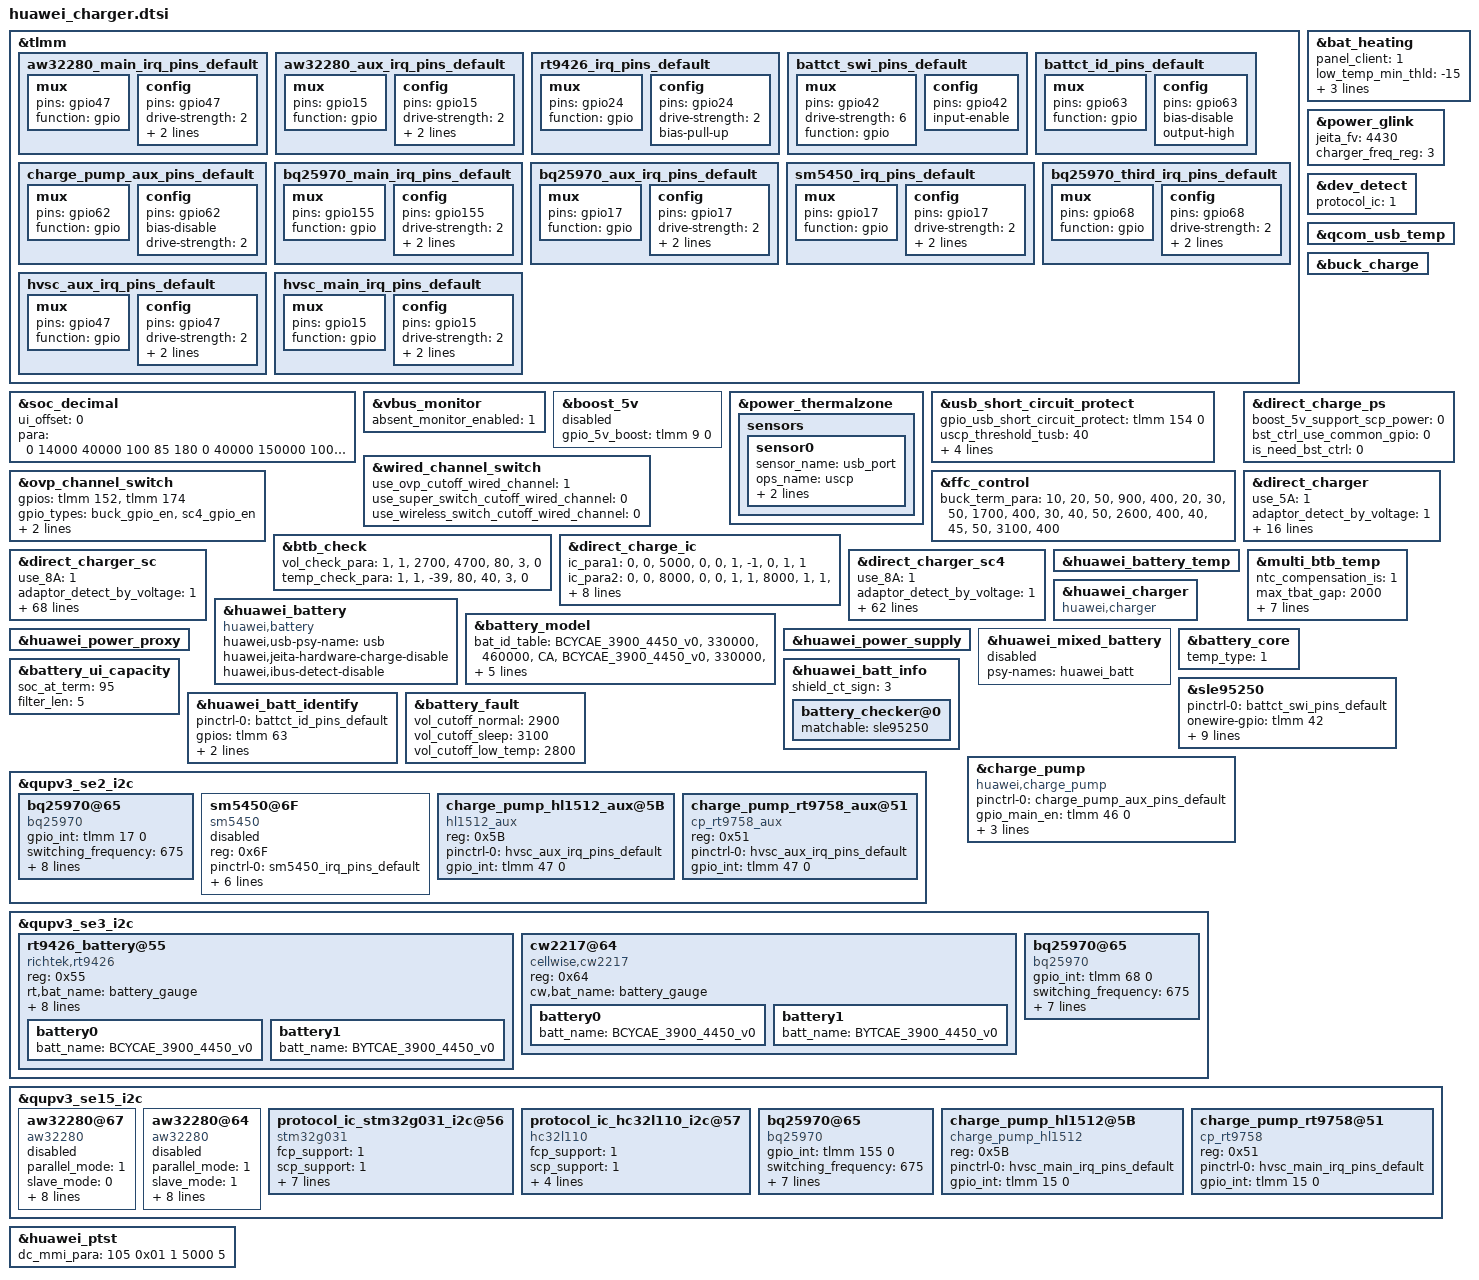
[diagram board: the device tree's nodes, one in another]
&tlmm {
	aw32280_main_irq_pins_default: aw32280_main_irq_pins_default {
		mux {
			pins = "gpio47";
			function = "gpio";
		};
		config {
			pins = "gpio47";
			drive-strength = <2>;
			bias-pull-up;
			input-enable;
		};
	};

	aw32280_aux_irq_pins_default: aw32280_aux_irq_pins_default {
		mux {
			pins = "gpio15";
			function = "gpio";
		};
		config {
			pins = "gpio15";
			drive-strength = <2>;
			bias-pull-up;
			input-enable;
		};
	};


	rt9426_irq_pins_default: rt9426_irq_pins_default {
		mux {
			pins = "gpio24";
			function = "gpio";
		};
		config {
			pins = "gpio24";
			drive-strength = <2>;
			bias-pull-up;
		};
	};
	battct_swi_pins_default: battct_swi_pins_default {
		mux {
			pins = "gpio42";
			drive-strength = <6>;
			function = "gpio";
		};
		config {
			pins = "gpio42";
			input-enable;
		};
	};
	battct_id_pins_default: battct_id_pins_default {
		mux {
			pins = "gpio63";
			function = "gpio";
		};
		config {
			pins = "gpio63";
			bias-disable;
			output-high;
		};
	};
	charge_pump_aux_pins_default: charge_pump_aux_pins_default {
		/* MCLK4 */
		mux {
			pins = "gpio62";
			function = "gpio";
		};
		config {
			pins = "gpio62";
			bias-disable; /* No PULL */
			drive-strength = <2>; /* 2 MA */
		};
	};
	bq25970_main_irq_pins_default: bq25970_main_irq_pins_default {
		mux {
			pins = "gpio155";
			function = "gpio";
		};
		config {
			pins = "gpio155";
			drive-strength = <2>;
			bias-pull-up;
			input-enable;
		};
	};

	bq25970_aux_irq_pins_default: bq25970_aux_irq_pins_default {
		mux {
			pins = "gpio17";
			function = "gpio";
		};
		config {
			pins = "gpio17";
			drive-strength = <2>;
			bias-pull-up;
			input-enable;
		};
	};

	sm5450_irq_pins_default: sm5450_irq_pins_default {
		mux {
			pins = "gpio17";
			function = "gpio";
		};
		config {
			pins = "gpio17";
			drive-strength = <2>;
			bias-pull-up;
			input-enable;
		};
	};

	bq25970_third_irq_pins_default: bq25970_third_irq_pins_default {
		mux {
			pins = "gpio68";
			function = "gpio";
		};
		config {
			pins = "gpio68";
			drive-strength = <2>;
			bias-pull-up;
			input-enable;
		};
	};

	hvsc_aux_irq_pins_default: hvsc_aux_irq_pins_default {
		mux {
			pins = "gpio47";
			function = "gpio";
		};
		config {
			pins = "gpio47";
			drive-strength = <2>;
			bias-pull-up;
			input-enable;
		};
	};

	hvsc_main_irq_pins_default: hvsc_main_irq_pins_default {
		mux {
			pins = "gpio15";
			function = "gpio";
		};
		config {
			pins = "gpio15";
			drive-strength = <2>;
			bias-pull-up;
			input-enable;
		};
	};
};

&bat_heating {
	panel_client = "1";
	low_temp_min_thld = "-15";
	low_temp_min_ibat = "-550";
	temp_para =
		"-32767", "0", "0",
		"0", "5", "-1",
		"5", "10", "400",
		"10", "20", "2500",
		"20", "45", "4500",
		"45", "32767", "0";
	status = "ok";
};

&soc_decimal {
	ui_offset = <0>;
	para = <
		0 14000 40000  100 85  180
		0 40000 150000 100 120 100
		1 20000 27000  100 85  140
		1 27000 100000 100 85  140
	>;
	status = "ok";
};

&power_glink {
	jeita_fv = <4430>;
	charger_freq_reg = <3>;
};

&dev_detect {
	protocol_ic = <1>;
};

&vbus_monitor {
	status = "ok";
	absent_monitor_enabled = <1>;
};

&boost_5v {
	gpio_5v_boost = <&tlmm 9 0>; /* GPIO_09 */
	status = "disabled";
};

&power_thermalzone {
	status = "ok";
	sensors{
		sensor0 {
			sensor_name = "usb_port";
			ops_name = "uscp";
			adc_channel = <0>;
			ntc_index = <5>;
		};
	};
};

&qcom_usb_temp {
	status = "ok";
};

&usb_short_circuit_protect {
	gpio_usb_short_circuit_protect = <&tlmm 154 0>; /* GPIO_154 */
	uscp_threshold_tusb = <40>;
	open_mosfet_temp = <30>;
	close_mosfet_temp = <10>;
	open_hiz_temp = <30>;
	interval_switch_temp = <15>;
	status = "ok";
};

&wired_channel_switch {
	use_ovp_cutoff_wired_channel = <1>;
	use_super_switch_cutoff_wired_channel = <0>;
	use_wireless_switch_cutoff_wired_channel = <0>;
	status = "ok";
};

&ovp_channel_switch {
	gpios = <&tlmm 152 0 &tlmm 174 0>;
	gpio_types = "buck_gpio_en", "sc4_gpio_en";
	gpio_en_status = <0 1>;
	gpio_low_by_set_input = <0>;
	status = "ok";
};

&buck_charge {
	status = "ok";
};

&ffc_control {
	status = "ok";
	buck_term_para =
		"10", "20", "50", "900", "400",
		"20", "30", "50", "1700", "400",
		"30", "40", "50", "2600", "400",
		"40", "45", "50", "3100", "400";
};

&btb_check {
	vol_check_para = "1", "1", "2700", "4700", "80", "3", "0";
	temp_check_para = "1", "1", "-39", "80", "40", "3", "0";
	status = "ok";
};

&direct_charge_ps {
	boost_5v_support_scp_power = <0>;
	bst_ctrl_use_common_gpio = <0>;
	is_need_bst_ctrl = <0>;
	status = "ok";
};

&direct_charge_ic {
	/* The IC_PARA table is used to find the relationship between chip and path */
	/* the chip's current passing capacity */
	/* and the sampling points of battery voltage and current */
	/* ic_index  path_index  max_ibat  ibat_sample_point  vbat_sample_point */
	ic_para1 =
		"0", "0", "5000", "0", "0",
		"1", "-1", "0", "1", "1";
	ic_para2 =
		"0", "0", "8000", "0", "0",
		"1", "1", "8000", "1", "1",
		"2", "1", "8000", "1", "1";
	ic_para3 =
		"0", "0", "9000", "0", "0",
		"1", "1", "8000", "1", "1",
		"2", "1", "8000", "1", "1";
	mode_para =
		"lvc_mode", "ic_para1",
		"sc_mode", "ic_para2",
		"sc4_mode", "ic_para3";
	use_two_stage = <1>;
	use_coul_ibat = <1>;
	use_coul_vbat = <1>;
	status = "ok";
};

&direct_charger {
	use_5A = <1>;
	adaptor_detect_by_voltage = <1>;
	need_wired_sw_off = <0>;
	volt_para =
		"4300", "4500", "4000",
		"4410", "4000", "2000";
	compensate_r = <11>;
	all_stage_compensate_r_en = <1>;
	cc_cable_detect_enable = <1>;
	vol_err_th = <250>;
	full_path_res_max = <300>;
	scp_work_on_charger = <1>;
	init_delt_vset = <300>;
	standard_cable_full_path_res_max = <300>;
	first_cc_stage_timer_in_min = <5>;
	stage_need_to_jump = "1";
	low_temp_hysteresis = <5>;
	temp_para =
		"-32767", "10", "0",
		"10", "45", "5000",
		"45", "32767", "0";
	rt_test_para =
		"1000", "105"; /* rt_curr_th rt_test_time */
	status = "ok";

};

&direct_charger_sc {
	use_8A = <1>;
	adaptor_detect_by_voltage = <1>;
	need_wired_sw_off = <0>;
	dc_volt_ratio = <2>;
	init_delt_vset = <450>;
	max_adaptor_vset = <11000>;
	init_adapter_vset = <8800>;
	vol_err_th = <500>;
	adaptor_leakage_current_th = <600>;
	vstep = <20>;
	min_dc_bat_vol = <3450>;
	max_dc_bat_vol = <4380>;
	max_current_for_none_standard_cable = <6000>;
	stop_charging_sleep_enable = <1>;
	delta_err = <200>;
	adaptor_antifake_check_enable = <1>;
	adaptor_antifake_key_index = <2>;
	support_multi_ic = <1>;
	multi_ic_ibat_th = <5000>;
	second_resist_check_en = <1>;
	ui_max_pwr = <40000>;
	product_max_pwr = <66000>;
	volt_para =
		"4150", "12000", "8000",
		"4250", "8000", "6000",
		"4300", "6000", "4000",
		"4430", "4000", "2800",
		"4460", "2800", "900";
	volt_para1 =
		"4200", "13200", "12000",
		"4300", "12000", "8000",
		"4400", "8000", "6000",
		"4430", "6000", "4800",
		"4460", "4800", "1600";
	volt_para2 =
		"4200", "13200", "12000",
		"4300", "12000", "8000",
		"4400", "8000", "6000",
		"4430", "6000", "4800",
		"4460", "4800", "2600";
	volt_para3 =
		"4200", "13200", "12000",
		"4300", "12000", "8000",
		"4400", "8000", "6000",
		"4430", "6000", "4800",
		"4460", "4800", "3100";
	time_para =
		"1380", "6200",
		"1320", "8300",
		"1020", "9300",
		"480", "9500",
		"0", "13200";
	bat_para =
		"CAE", "10", "20", "volt_para",
		"CAE", "20", "30", "volt_para1",
		"CAE", "30", "40", "volt_para2",
		"CAE", "40", "45", "volt_para3",
		"default", "10", "20", "volt_para",
		"default", "20", "30", "volt_para1",
		"default", "30", "40", "volt_para2",
		"default", "40", "45", "volt_para3";
	vstep_para =
			"2000", "80";
	compensate_r = <11>;
	all_stage_compensate_r_en = <1>;
	cc_cable_detect_enable = <1>;
	full_path_res_max = <500>;
	scp_work_on_charger = <1>;
	standard_cable_full_path_res_max = <500>;
	first_cc_stage_timer_in_min = <14>;
	stage_need_to_jump = "-1";
	low_temp_hysteresis = <5>;
	rt_test_para =
		/* first:sc second:mainsc third:auxsc */
		"500", "105",
		"500", "105",
		"500", "105";
	current_ratio =
		"3", "4", "12", "2", "-1",
		"3", "5", "10", "1", "8000",
		"0", "5", "10", "0", "0";
	vbat_error =
		"3", "140", "2", "-1",
		"3", "100", "1", "0";
	temp_para =
		"-32767", "10", "0",
		"10", "45", "13200",
		"45", "32767", "0";
	resist_para =
		"0", "300", "6000",
		"300", "600", "4000";
	std_resist_para =
		"0", "300", "0",
		"300", "600", "4000";
	second_resist_para =
		"0", "180", "0",
		"180", "600", "8000";
	ctc_second_resist_para =
		"0", "250", "0",
		"250", "600", "8000";
	adapter_max_power_time_para =
		"3", "600", "6000",
		"4", "1200", "3000",
		"5", "600", "6000",
		"6", "600", "6000",
		"7", "600", "6000",
		"8", "600", "6000",
		"9", "1200", "3000",
		"10", "1200", "3000",
		"11", "120", "8000",
		"12", "600", "6000",
		"13", "600", "6000",
		"14", "600", "6000",
		"15", "1200", "3000",
		"16", "120", "8000",
		"18", "120", "8000",
		"24", "120", "8000",
		"25", "120", "8000",
		"28", "120", "7500";
	status = "ok";
};

&direct_charger_sc4 {
	use_8A = <1>;
	adaptor_detect_by_voltage = <1>;
	need_wired_sw_off = <1>;
	dc_volt_ratio = <4>;
	init_delt_vset = <900>;
	charge_time = <60>;
	max_adaptor_vset = <20000>;
	init_adapter_vset = <15000>;
	vol_err_th = <500>;
	adaptor_leakage_current_th = <600>;
	vstep = <40>;
	min_dc_bat_vol = <3450>;
	max_dc_bat_vol = <4380>;
	max_current_for_none_standard_cable = <12000>;
	delta_err = <800>;
	adaptor_antifake_check_enable = <1>;
	adaptor_antifake_key_index = <2>;
	support_multi_ic = <1>;
	multi_ic_ibat_th = <5000>;
	second_resist_check_en = <1>;
	ui_max_pwr = <40000>;
	product_max_pwr = <100000>;
	volt_para =
		"4150", "12000", "8000",
		"4250", "8000", "6000",
		"4300", "6000", "4000",
		"4430", "4000", "2800",
		"4460", "2800", "900";
	volt_para1 =
		"4100", "20000", "16000",
		"4200", "16000", "12000",
		"4300", "12000", "8000",
		"4400", "8000", "6000",
		"4430", "6000", "4800",
		"4460", "4800", "1600";
	volt_para2 =
		"4100", "20000", "16000",
		"4200", "16000", "12000",
		"4300", "12000", "8000",
		"4400", "8000", "6000",
		"4430", "6000", "4800",
		"4460", "4800", "2600";
	volt_para3 =
		"4100", "20000", "16000",
		"4200", "16000", "12000",
		"4300", "12000", "8000",
		"4400", "8000", "6000",
		"4430", "6000", "4800",
		"4460", "4800", "3100";
	time_para =
		"1140", "6200",
		"960", "8200",
		"300", "9200",
		"90", "13200",
		"0", "20000";
	bat_para =
		"CAE", "10", "20", "volt_para",
		"CAE", "20", "30", "volt_para1",
		"CAE", "30", "40", "volt_para2",
		"CAE", "40", "45", "volt_para3",
		"default", "10", "20", "volt_para",
		"default", "20", "30", "volt_para1",
		"default", "30", "40", "volt_para2",
		"default", "40", "45", "volt_para3";
	vstep_para =
			"2000", "160";
	compensate_r = <11>;
	all_stage_compensate_r_en = <1>;
	cc_cable_detect_enable = <1>;
	full_path_res_max = <580>;
	scp_work_on_charger = <1>;
	standard_cable_full_path_res_max = <580>;
	ctc_cable_full_path_res_max = <400>;
	first_cc_stage_timer_in_min = <14>;
	stage_need_to_jump = "-1";
	low_temp_hysteresis = <5>;
	rt_test_para =
		/* first:sc4 second:mainsc4 third:auxsc4 */
		"5000", "105",
		"500", "0",
		"500", "0";
	current_ratio =
		"3", "4", "12", "2", "-1",
		"3", "5", "10", "1", "8000",
		"0", "5", "10", "0", "0";
	vbat_error =
		"3", "140", "2", "-1",
		"3", "100", "1", "0";
	temp_para =
		"-32767", "10", "0",
		"10", "45", "20000",
		"45", "32767", "0";
	resist_para =
		"0", "380", "12000",
		"380", "600", "8000";
	std_resist_para =
		"0", "380", "0",
		"380", "600", "8000";
	second_resist_para =
		"0", "260", "0",
		"260", "600", "16000";
	ctc_second_resist_para =
		"0", "330", "0",
		"330", "600", "16000";
	status = "ok";
};

&huawei_battery_temp {
	status = "ok";
};

&multi_btb_temp {
	status = "ok";
	ntc_compensation_is = <1>;
	max_tbat_gap = <2000>;
	comp_para =
		"17000", "17000",
		"15000", "15000",
		"13000", "13000",
		"11000", "11000",
		"9000", "8000",
		"7000", "5000",
		"6000", "4000",
		"5000", "3000",
		"3000", "2000",
		"2000", "1000";
	comp_para1 =
		"0", "0";
	sensor-names =
		"battery_gauge", "comp_para",
		"bk_battery", "comp_para1";
};

&huawei_battery {
	compatible = "huawei,battery";
	status = "ok";
	huawei,usb-psy-name = "usb";
	huawei,jeita-hardware-charge-disable;
	huawei,ibus-detect-disable;
};

&huawei_charger {
	compatible = "huawei,charger";
	status = "ok";
};


&battery_model {
	bat_id_table =
		"BCYCAE_3900_4450_v0", "330000", "460000", "CA",
		"BCYCAE_3900_4450_v0", "330000", "460000", "CZ",
		"BYTCAE_3900_4450_v0", "330000", "460000", "YA",
		"BYTCAE_3900_4450_v0", "330000", "460000", "YZ";
	design_fcc = <3900>;
	id_adc_channel = <0>; /* useless but necessary for Qcom, set 0 as default */
	status = "ok";
};

&huawei_power_proxy {
	status = "ok";
};

&huawei_power_supply {
	 status = "ok";
};

&huawei_mixed_battery {
	psy-names = "huawei_batt";
	status = "disabled";
};

&battery_core {
	temp_type = <1>;
	status = "ok";
};

&battery_ui_capacity {
	soc_at_term = <95>;
	filter_len = <5>;
	status = "ok";
};

&sle95250 {
        pinctrl-names = "default";
        pinctrl-0 = <&battct_swi_pins_default>;
        onewire-gpio = <&tlmm 42 0>;
        product_id0 = <1>;
        product_id2 = <3>;
        gpio_sn_mode_val = <0>;
        dip_check = <0>;
        gpio_swi = <42>;
        gpio_id_mode = <63>;
        gpio_swi_drv = <2>;
        tau = /bits/ 8 <0xa>;
        tau_fastboot = <7>;
        status = "ok";
};

&huawei_batt_info {
        status = "ok";
        shield_ct_sign = <3>;
        battery_checker@0 {
                matchable = <&sle95250>;
                status = "ok";
        };
};

&huawei_batt_identify {
	pinctrl-names = "default";
	pinctrl-0 = <&battct_id_pins_default>;
	gpios = <&tlmm 63 0>;
	id_voltage_gpiov = <0 1>;
	id_sn_gpiov = <0 0>;
	status = "ok";
};

&battery_fault {
	vol_cutoff_normal = <2900>;
	vol_cutoff_sleep = <3100>;
	vol_cutoff_low_temp = <2800>;
	status = "ok";
};

&charge_pump {
	compatible = "huawei,charge_pump";
	pinctrl-names = "default";
	pinctrl-0 = <&charge_pump_aux_pins_default>;
	gpio_main_en = <&tlmm 46 0>;
	gpio_main_cp_en_val = <0>;
	gpio_aux_en = <&tlmm 62 0>;
	gpio_aux_cp_en_val = <0>;
	status = "ok";
};

&qupv3_se2_i2c {
	status = "ok";
	bq25970@65 {
		compatible = "bq25970";
		gpio_int = <&tlmm 17 0>;
		switching_frequency = <675>;
		reg = <0x65>;
		pinctrl-names = "default";
		pinctrl-0 = <&bq25970_aux_irq_pins_default>;
		ic_role = <1>;
		freq_para =
			"sc_sc8551", "300";
		ibus_low_deglitch = <5>;
		lvc_batinfo_enable = <1>;
		sense_r_actual = <10>;
		resume_need_wait_i2c = <1>;
		status = "ok";
	};

	sm5450@6F{
		compatible = "sm5450";
		reg = <0x6F>;
		pinctrl-names = "default";
		pinctrl-0 = <&sm5450_irq_pins_default>;
		intr_gpio_num = <17>; /* direct defined GPIO num */
		intr_gpio = <&tlmm 17 0>;
		fcp_support = <1>;
		scp_support = <1>;
		sense_r_actual = <10>;
		ic_role = <1>;
		status = "disabled";
	};

	charge_pump_hl1512_aux@5B {
		compatible = "hl1512_aux";
		reg = <0x5B>;
		pinctrl-names = "hvsc_aux_irq_pins_default";
		pinctrl-0 = <&hvsc_aux_irq_pins_default>;
		gpio_int = <&tlmm 47 0>;
		status = "ok";
	};

	charge_pump_rt9758_aux@51 {
		compatible = "cp_rt9758_aux";
		reg = <0x51>;
		pinctrl-names = "hvsc_aux_irq_pins_default";
		pinctrl-0 = <&hvsc_aux_irq_pins_default>;
		gpio_int = <&tlmm 47 0>;
		status = "ok";
	};
};

&qupv3_se3_i2c {
	status = "ok";
	rt9426_battery@55{
		reg = <0x55>;
		compatible = "richtek,rt9426";
		rt,bat_name = "battery_gauge";
		pinctrl-names = "default";
		pinctrl-0 = <&rt9426_irq_pins_default>;
		rt9426,gpio-intb = <&tlmm 24 0x0>;
		need_reset_version = <9>;
		rt_config_ver = <11>;
		ntc_compensation_is = <1>;
		ntc_temp_compensation_para =
			"17000", "170",
			"15000", "150",
			"13000", "130",
			"11000", "110",
			"9000", "80",
			"7000", "50",
			"6000", "40",
			"5000", "30",
			"3000", "20",
			"2000", "10";
		status = "ok";
		battery0{
			batt_name = "BCYCAE_3900_4450_v0";
			#include "../../../huawei_charger/rt9426_BITCAE_4V45_3900mah_RENA_BT216.dtsi"
		};
		battery1{
			batt_name = "BYTCAE_3900_4450_v0";
			#include "../../../huawei_charger/rt9426_BITCAE_4V45_3900mah_RENA_BT216.dtsi"
		};
	};

	cw2217@64 {
		compatible = "cellwise,cw2217";
		reg = <0x64>;
		cw,bat_name = "battery_gauge";
		status = "ok";
		battery0{
			batt_name = "BCYCAE_3900_4450_v0";
			#include "../../../huawei_charger/cw2217_0P5mohm_BCYCAE_3900mAh_4V45_RNA_BT216.dtsi"
		};
		battery1{
			batt_name = "BYTCAE_3900_4450_v0";
			#include "../../../huawei_charger/cw2217_0P5mohm_BYTCAE_3900mAh_4V45_RNA_BT216.dtsi"
		};
	};

	bq25970@65 {
		compatible = "bq25970";
		gpio_int = <&tlmm 68 0>;
		switching_frequency = <675>;
		reg = <0x65>;
		pinctrl-names = "default";
		pinctrl-0 = <&bq25970_third_irq_pins_default>;
		ic_role = <2>;
		freq_para =
			"sc_sc8551", "300";
		ibus_low_deglitch = <5>;
		sense_r_actual = <10>;
		resume_need_wait_i2c = <1>;
		status = "ok";
	};
};

&qupv3_se15_i2c {
	#address-cells = <1>;
	#size-cells = <0>;
	status = "ok";
	aw32280@67{
		compatible = "aw32280";
		parallel_mode = <1>;
		slave_mode = <0>;
		ic_role = <0>;
		reg = <0x67>;
		gpio_reset = <&tlmm 155 0>;
		pinctrl-names = "default";
		pinctrl-0 = <&aw32280_main_irq_pins_default>;
		gpio_int = <&tlmm 47 0>;
		gpio_enable = <&tlmm 62 0>;
		sense_r_config = <20>;
		sense_r_actual = <20>;
		status = "disabled";
	};

	aw32280@64{
		compatible = "aw32280";
		parallel_mode = <1>;
		slave_mode = <1>;
		ic_role = <1>;
		reg = <0x64>;
		gpio_reset = <&tlmm 17 0>;
		pinctrl-names = "default";
		pinctrl-0 = <&aw32280_aux_irq_pins_default>;
		gpio_int = <&tlmm 15 0>;
		gpio_enable = <&tlmm 46 0>;
		sense_r_config = <20>;
		sense_r_actual = <20>;
		status = "disabled";
	};

	protocol_ic_stm32g031_i2c@56 {
		compatible = "stm32g031";
		fcp_support = <1>;
		scp_support = <1>;
		ufcs_support = <1>;
		wait_time = <20>;
		hw_config = <0x20>;
		gpio_enable = <&tlmm 136 0>;
		gpio_reset = <&tlmm 33 0>;
		gpio_int = <&tlmm 16 0>;
		reg = <0x56>;
		status = "ok";
	};

	protocol_ic_hc32l110_i2c@57 {
		compatible = "hc32l110";
		fcp_support = <1>;
		scp_support = <1>;
		wait_time = <50>;
		gpio_enable = <&tlmm 136 0>;
		gpio_reset = <&tlmm 79 0>;
		reg = <0x57>;
		status = "ok";
	};

	bq25970@65 {
		compatible = "bq25970";
		gpio_int = <&tlmm 155 0>;
		switching_frequency = <675>;
		reg = <0x65>;
		pinctrl-names = "default";
		pinctrl-0 = <&bq25970_main_irq_pins_default>;
		ic_role = <0>;
		freq_para =
			"sc_sc8551", "300";
		ibus_low_deglitch = <5>;
		sense_r_actual = <10>;
		resume_need_wait_i2c = <1>;
		status = "ok";
	};

	charge_pump_hl1512@5B {
		compatible = "charge_pump_hl1512";
		reg = <0x5B>;
		pinctrl-names = "hvsc_main_irq_pins_default";
		pinctrl-0 = <&hvsc_main_irq_pins_default>;
		gpio_int = <&tlmm 15 0>;
		status = "ok";
	};

	charge_pump_rt9758@51 {
		compatible = "cp_rt9758";
		reg = <0x51>;
		pinctrl-names = "hvsc_main_irq_pins_default";
		pinctrl-0 = <&hvsc_main_irq_pins_default>;
		gpio_int = <&tlmm 15 0>;
		status = "ok";
	};
};

&huawei_ptst {
	dc_mmi_para = <105 0x01 1 5000 5>;
	status = "ok";
};
